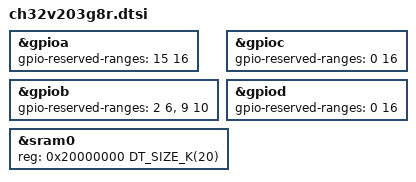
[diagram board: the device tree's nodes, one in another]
/*
 * Copyright (c) 2025 MASSDRIVER EI (massdriver.space)
 *
 * SPDX-License-Identifier: Apache-2.0
 */

#include <wch/ch32v203/ch32v203.dtsi>

&gpioa {
	gpio-reserved-ranges = <15 16>;
};

&gpiob {
	gpio-reserved-ranges = <2 6>, <9 10>;
};

&gpioc {
	gpio-reserved-ranges = <0 16>;
};

&gpiod {
	gpio-reserved-ranges = <0 16>;
};

&sram0 {
	reg = <0x20000000 DT_SIZE_K(20)>;
};
